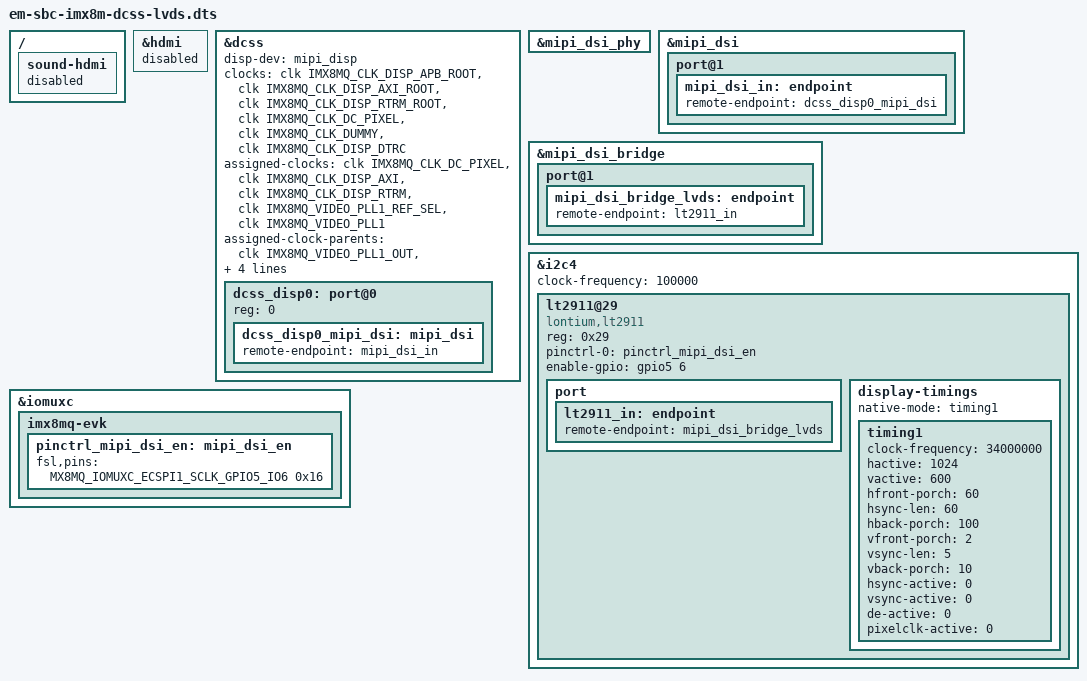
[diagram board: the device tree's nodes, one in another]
/*
 * Copyright 2019 EMBEST
 *
 * This program is free software; you can redistribute it and/or
 * modify it under the terms of the GNU General Public License
 * as published by the Free Software Foundation; either version 2
 * of the License, or (at your option) any later version.
 *
 * This program is distributed in the hope that it will be useful,
 * but WITHOUT ANY WARRANTY; without even the implied warranty of
 * MERCHANTABILITY or FITNESS FOR A PARTICULAR PURPOSE.  See the
 * GNU General Public License for more details.
 */

#include "em-sbc-imx8m.dts"

/ {
	sound-hdmi {
		status = "disabled";
	};
};

&hdmi {
	status = "disabled";
};

&dcss {
	status = "okay";
	disp-dev = "mipi_disp";

	clocks = <&clk IMX8MQ_CLK_DISP_APB_ROOT>,
		 <&clk IMX8MQ_CLK_DISP_AXI_ROOT>,
		 <&clk IMX8MQ_CLK_DISP_RTRM_ROOT>,
		 <&clk IMX8MQ_CLK_DC_PIXEL>,
		 <&clk IMX8MQ_CLK_DUMMY>,
		 <&clk IMX8MQ_CLK_DISP_DTRC>;
	clock-names = "apb", "axi", "rtrm", "pix_div", "pix_out", "dtrc";

	assigned-clocks = <&clk IMX8MQ_CLK_DC_PIXEL>,
			  <&clk IMX8MQ_CLK_DISP_AXI>,
			  <&clk IMX8MQ_CLK_DISP_RTRM>,
			  <&clk IMX8MQ_VIDEO_PLL1_REF_SEL>,
			  <&clk IMX8MQ_VIDEO_PLL1>;
	assigned-clock-parents = <&clk IMX8MQ_VIDEO_PLL1_OUT>,
				 <&clk IMX8MQ_SYS1_PLL_800M>,
				 <&clk IMX8MQ_SYS1_PLL_800M>,
				 <&clk IMX8MQ_CLK_25M>;
	assigned-clock-rates = <600000000>,
			       <800000000>,
			       <0>,
			       <400000000>,
			       <599999999>;

	dcss_disp0: port@0 {
		reg = <0>;

		dcss_disp0_mipi_dsi: mipi_dsi {
			remote-endpoint = <&mipi_dsi_in>;
		};
	};
};

&mipi_dsi_phy {
	status = "okay";
};

&mipi_dsi {
	status = "okay";

	port@1 {
		mipi_dsi_in: endpoint {
			remote-endpoint = <&dcss_disp0_mipi_dsi>;
		};
	};

};

&mipi_dsi_bridge {
	status = "okay";

    port@1 {
		mipi_dsi_bridge_lvds: endpoint {
			remote-endpoint = <&lt2911_in>;
		};
	};
};

&i2c4 {
	clock-frequency = <100000>;

    lt2911@29 {
		compatible = "lontium,lt2911";
		reg = <0x29>;
        pinctrl-0 = <&pinctrl_mipi_dsi_en>;
        enable-gpio = <&gpio5 6 GPIO_ACTIVE_HIGH>;

		port {
			lt2911_in: endpoint {
				remote-endpoint = <&mipi_dsi_bridge_lvds>;
			};
		};

		display-timings {
			native-mode = <&timing1>;
			timing1: timing1 {
				clock-frequency = <34000000>;
				hactive = <1024>;
				vactive = <600>;
				hfront-porch = <60>;
				hsync-len = <60>;
				hback-porch = <100>;
				vfront-porch = <2>;
				vsync-len = <5>;
				vback-porch = <10>;
				hsync-active = <0>;
				vsync-active = <0>;
				de-active = <0>;
				pixelclk-active = <0>;
			};
		};
	};

};

&iomuxc {
	imx8mq-evk {
		pinctrl_mipi_dsi_en: mipi_dsi_en {
			fsl,pins = <
				MX8MQ_IOMUXC_ECSPI1_SCLK_GPIO5_IO6	0x16 /*DSI_EN*/
			>;
		};

	};
};

